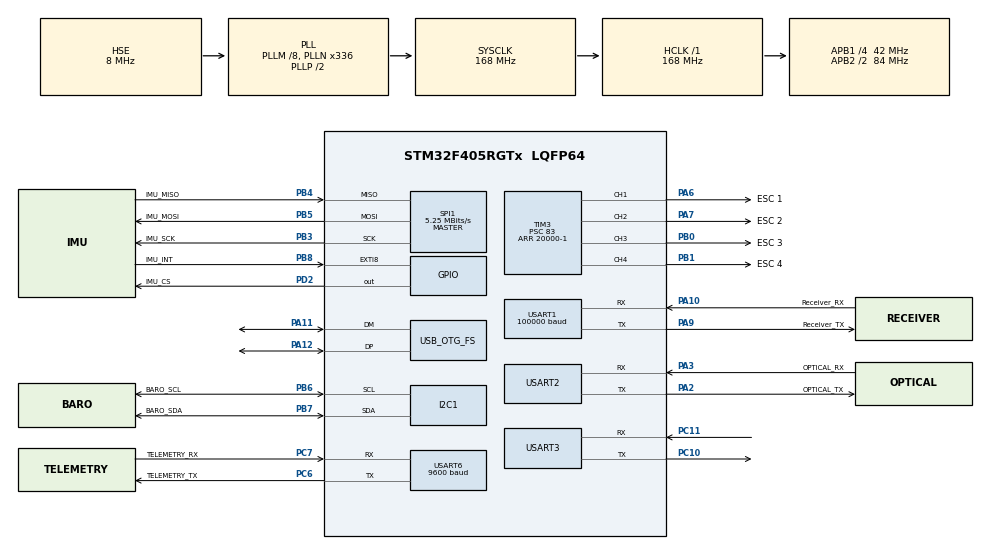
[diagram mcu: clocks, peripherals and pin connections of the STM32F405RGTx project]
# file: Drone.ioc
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Dma.Request0=USART2_RX
Dma.Request1=USART6_TX
Dma.Request2=USART2_TX
Dma.Request3=USART1_RX
Dma.Request4=SPI1_RX
Dma.Request5=SPI1_TX
Dma.SPI1_RX.4.Direction=DMA_PERIPH_TO_MEMORY
Dma.SPI1_RX.4.FIFOMode=DMA_FIFOMODE_DISABLE
Dma.SPI1_RX.4.Instance=DMA2_Stream0
Dma.SPI1_RX.4.MemDataAlignment=DMA_MDATAALIGN_BYTE
Dma.SPI1_RX.4.MemInc=DMA_MINC_ENABLE
Dma.SPI1_RX.4.Mode=DMA_NORMAL
Dma.SPI1_RX.4.PeriphDataAlignment=DMA_PDATAALIGN_BYTE
Dma.SPI1_RX.4.PeriphInc=DMA_PINC_DISABLE
Dma.SPI1_RX.4.Priority=DMA_PRIORITY_VERY_HIGH
Dma.SPI1_TX.5.Direction=DMA_MEMORY_TO_PERIPH
Dma.SPI1_TX.5.FIFOMode=DMA_FIFOMODE_DISABLE
Dma.SPI1_TX.5.Instance=DMA2_Stream3
Dma.SPI1_TX.5.MemDataAlignment=DMA_MDATAALIGN_BYTE
Dma.SPI1_TX.5.MemInc=DMA_MINC_ENABLE
Dma.SPI1_TX.5.Mode=DMA_NORMAL
Dma.SPI1_TX.5.PeriphDataAlignment=DMA_PDATAALIGN_BYTE
Dma.SPI1_TX.5.PeriphInc=DMA_PINC_DISABLE
Dma.SPI1_TX.5.Priority=DMA_PRIORITY_HIGH
Dma.USART1_RX.3.Direction=DMA_PERIPH_TO_MEMORY
Dma.USART1_RX.3.FIFOMode=DMA_FIFOMODE_DISABLE
Dma.USART1_RX.3.Instance=DMA2_Stream2
Dma.USART1_RX.3.MemDataAlignment=DMA_MDATAALIGN_BYTE
Dma.USART1_RX.3.MemInc=DMA_MINC_ENABLE
Dma.USART1_RX.3.Mode=DMA_CIRCULAR
Dma.USART1_RX.3.PeriphDataAlignment=DMA_PDATAALIGN_BYTE
Dma.USART1_RX.3.PeriphInc=DMA_PINC_DISABLE
Dma.USART1_RX.3.Priority=DMA_PRIORITY_HIGH
Dma.USART2_RX.0.Direction=DMA_PERIPH_TO_MEMORY
Dma.USART2_RX.0.FIFOMode=DMA_FIFOMODE_DISABLE
Dma.USART2_RX.0.Instance=DMA1_Stream5
Dma.USART2_RX.0.MemDataAlignment=DMA_MDATAALIGN_BYTE
Dma.USART2_RX.0.MemInc=DMA_MINC_ENABLE
Dma.USART2_RX.0.Mode=DMA_CIRCULAR
Dma.USART2_RX.0.PeriphDataAlignment=DMA_PDATAALIGN_BYTE
Dma.USART2_RX.0.PeriphInc=DMA_PINC_DISABLE
Dma.USART2_RX.0.Priority=DMA_PRIORITY_LOW
Dma.USART2_TX.2.Direction=DMA_MEMORY_TO_PERIPH
Dma.USART2_TX.2.FIFOMode=DMA_FIFOMODE_DISABLE
Dma.USART2_TX.2.Instance=DMA1_Stream6
Dma.USART2_TX.2.MemDataAlignment=DMA_MDATAALIGN_BYTE
Dma.USART2_TX.2.MemInc=DMA_MINC_ENABLE
Dma.USART2_TX.2.Mode=DMA_NORMAL
Dma.USART2_TX.2.PeriphDataAlignment=DMA_PDATAALIGN_BYTE
Dma.USART2_TX.2.PeriphInc=DMA_PINC_DISABLE
Dma.USART2_TX.2.Priority=DMA_PRIORITY_LOW
Dma.USART6_TX.1.Direction=DMA_MEMORY_TO_PERIPH
Dma.USART6_TX.1.FIFOMode=DMA_FIFOMODE_DISABLE
Dma.USART6_TX.1.Instance=DMA2_Stream6
Dma.USART6_TX.1.MemDataAlignment=DMA_MDATAALIGN_BYTE
Dma.USART6_TX.1.MemInc=DMA_MINC_ENABLE
Dma.USART6_TX.1.Mode=DMA_NORMAL
Dma.USART6_TX.1.PeriphDataAlignment=DMA_PDATAALIGN_BYTE
Dma.USART6_TX.1.PeriphInc=DMA_PINC_DISABLE
Dma.USART6_TX.1.Priority=DMA_PRIORITY_LOW
FREERTOS.INCLUDE_uxTaskGetStackHighWaterMark=1
FREERTOS.INCLUDE_vTaskDelayUntil=1
FREERTOS.Tasks01=telemTask,-1,1024,StartTelemTask,Default,NULL,Dynamic,NULL,NULL
FREERTOS.configCHECK_FOR_STACK_OVERFLOW=2
FREERTOS.configTOTAL_HEAP_SIZE=25000
FREERTOS.configUSE_MALLOC_FAILED_HOOK=1
FREERTOS.configUSE_NEWLIB_REENTRANT=1
I2C1.I2C_Mode=I2C_Fast
IWDG.Prescaler=IWDG_PRESCALER_32
IWDG.Reload=99
Mcu.Family=STM32F4
Mcu.Name=STM32F405RGTx
Mcu.Package=LQFP64
NVIC.DMA1_Stream5_IRQn=true\:6\:0\:true\:false\:true\:true\:false\:true\:true
NVIC.DMA1_Stream6_IRQn=true\:6\:0\:true\:false\:true\:true\:false\:true\:true
NVIC.DMA2_Stream0_IRQn=true\:5\:0\:false\:false\:true\:true\:false\:true\:true
NVIC.DMA2_Stream2_IRQn=true\:6\:0\:true\:false\:true\:true\:false\:true\:true
NVIC.DMA2_Stream3_IRQn=true\:5\:0\:false\:false\:true\:true\:false\:true\:true
NVIC.DMA2_Stream6_IRQn=true\:6\:0\:true\:false\:true\:true\:false\:true\:true
NVIC.EXTI9_5_IRQn=true\:5\:0\:false\:false\:true\:true\:true\:true\:true
NVIC.OTG_FS_IRQn=true\:6\:0\:true\:false\:true\:true\:false\:true\:true
NVIC.PriorityGroup=NVIC_PRIORITYGROUP_4
NVIC.TIM7_IRQn=true\:0\:0\:true\:false\:true\:false\:false\:true\:true
NVIC.TimeBase=TIM7_IRQn
NVIC.TimeBaseIP=TIM7
NVIC.USART1_IRQn=true\:7\:0\:true\:false\:true\:true\:true\:true\:true
NVIC.USART2_IRQn=true\:6\:0\:true\:false\:true\:true\:false\:true\:true
NVIC.USART6_IRQn=true\:6\:0\:true\:false\:true\:true\:false\:true\:true
PA10.GPIO_Label=Receiver_RX
PA10.Mode=Asynchronous
PA10.Signal=USART1_RX
PA11.Mode=Device_Only
PA11.Signal=USB_OTG_FS_DM
PA12.Mode=Device_Only
PA12.Signal=USB_OTG_FS_DP
PA13.Mode=Serial_Wire
PA13.Signal=SYS_JTMS-SWDIO
PA14.Mode=Serial_Wire
PA14.Signal=SYS_JTCK-SWCLK
PA2.GPIO_Label=OPTICAL_TX
PA2.Mode=Asynchronous
PA2.Signal=USART2_TX
PA3.GPIO_Label=OPTICAL_RX
PA3.Mode=Asynchronous
PA3.Signal=USART2_RX
PA6.GPIO_Label=ESC 1
PA6.Signal=S_TIM3_CH1
PA7.GPIO_Label=ESC 2
PA7.Signal=S_TIM3_CH2
PA9.GPIO_Label=Receiver_TX
PA9.Mode=Asynchronous
PA9.Signal=USART1_TX
PB0.GPIO_Label=ESC 3
PB0.Signal=S_TIM3_CH3
PB1.GPIO_Label=ESC 4
PB1.Signal=S_TIM3_CH4
PB3.GPIO_Label=IMU_SCK
PB3.Mode=Full_Duplex_Master
PB3.Signal=SPI1_SCK
PB4.GPIO_Label=IMU_MISO
PB4.Mode=Full_Duplex_Master
PB4.Signal=SPI1_MISO
PB5.GPIO_Label=IMU_MOSI
PB5.Mode=Full_Duplex_Master
PB5.Signal=SPI1_MOSI
PB6.GPIO_Label=BARO_SCL
PB6.Mode=I2C
PB6.Signal=I2C1_SCL
PB7.GPIO_Label=BARO_SDA
PB7.Mode=I2C
PB7.Signal=I2C1_SDA
PB8.GPIO_Label=IMU_INT
PB8.Signal=GPXTI8
PC10.GPIO_ModeDefaultPP=GPIO_MODE_AF_PP
PC10.GPIO_PuPd=GPIO_NOPULL
PC10.GPIO_Speed=GPIO_SPEED_FREQ_VERY_HIGH
PC10.Mode=Asynchronous
PC10.Signal=USART3_TX
PC11.GPIO_ModeDefaultPP=GPIO_MODE_AF_PP
PC11.GPIO_PuPd=GPIO_NOPULL
PC11.GPIO_Speed=GPIO_SPEED_FREQ_VERY_HIGH
PC11.Mode=Asynchronous
PC11.Signal=USART3_RX
PC6.GPIO_Label=TELEMETRY_TX
PC6.Mode=Asynchronous
PC6.Signal=USART6_TX
PC7.GPIO_Label=TELEMETRY_RX
PC7.Mode=Asynchronous
PC7.Signal=USART6_RX
PD2.GPIO_Label=IMU_CS
PD2.PinState=GPIO_PIN_SET
PD2.Signal=GPIO_Output
PH0-OSC_IN.Mode=HSE-External-Oscillator
PH0-OSC_IN.Signal=RCC_OSC_IN
PH1-OSC_OUT.Mode=HSE-External-Oscillator
PH1-OSC_OUT.Signal=RCC_OSC_OUT
ProjectManager.HeapSize=0x200
ProjectManager.StackSize=0x400
ProjectManager.TargetToolchain=STM32CubeIDE
RCC.48MHZClocksFreq_Value=48000000
RCC.AHBFreq_Value=168000000
RCC.APB1CLKDivider=RCC_HCLK_DIV4
RCC.APB1Freq_Value=42000000
RCC.APB1TimFreq_Value=84000000
RCC.APB2CLKDivider=RCC_HCLK_DIV2
RCC.APB2Freq_Value=84000000
RCC.APB2TimFreq_Value=168000000
RCC.CortexFreq_Value=168000000
RCC.HCLKFreq_Value=168000000
RCC.HSE_VALUE=8000000
RCC.HSI_VALUE=16000000
RCC.LSE_VALUE=32768
RCC.PLLM=8
RCC.PLLN=336
RCC.PLLQ=7
RCC.SYSCLKFreq_VALUE=168000000
RCC.SYSCLKSource=RCC_SYSCLKSOURCE_PLLCLK
RCC.VCOOutputFreq_Value=336000000
SH.S_TIM3_CH1.0=TIM3_CH1,PWM Generation1 CH1
SH.S_TIM3_CH2.0=TIM3_CH2,PWM Generation2 CH2
SH.S_TIM3_CH3.0=TIM3_CH3,PWM Generation3 CH3
SH.S_TIM3_CH4.0=TIM3_CH4,PWM Generation4 CH4
SPI1.BaudRatePrescaler=SPI_BAUDRATEPRESCALER_16
SPI1.CalculateBaudRate=5.25 MBits/s
SPI1.Direction=SPI_DIRECTION_2LINES
SPI1.Mode=SPI_MODE_MASTER
SPI1.VirtualType=VM_MASTER
TIM3.AutoReloadPreload=TIM_AUTORELOAD_PRELOAD_ENABLE
TIM3.Channel-PWM\ Generation1\ CH1=TIM_CHANNEL_1
TIM3.Channel-PWM\ Generation2\ CH2=TIM_CHANNEL_2
TIM3.Channel-PWM\ Generation3\ CH3=TIM_CHANNEL_3
TIM3.Channel-PWM\ Generation4\ CH4=TIM_CHANNEL_4
TIM3.Period=20000-1
TIM3.Prescaler=83
USART1.BaudRate=100000
USART1.Parity=PARITY_EVEN
USART1.StopBits=STOPBITS_2
USART1.VirtualMode=VM_ASYNC
USART1.WordLength=WORDLENGTH_9B
USART2.VirtualMode=VM_ASYNC
USART3.VirtualMode=VM_ASYNC
USART3.WordLength=WORDLENGTH_8B
USART6.BaudRate=9600
USART6.VirtualMode=VM_ASYNC
USART6.WordLength=WORDLENGTH_8B
USB_DEVICE.CLASS_NAME_FS=CDC
USB_DEVICE.VirtualMode-CDC_FS=Cdc
USB_DEVICE.VirtualModeFS=Cdc_FS
USB_OTG_FS.VirtualMode=Device_Only
VP_FREERTOS_VS_CMSIS_V1.Mode=CMSIS_V1
VP_IWDG_VS_IWDG.Mode=IWDG_Activate
VP_SYS_VS_tim7.Mode=TIM7
VP_TIM2_VS_ClockSourceINT.Mode=Internal
VP_TIM3_VS_ClockSourceINT.Mode=Internal
VP_USB_DEVICE_VS_USB_DEVICE_CDC_FS.Mode=CDC_FS
board=custom

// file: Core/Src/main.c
/* USER CODE BEGIN Header */
/**
  ******************************************************************************
  * @file           : main.c
  * @brief          : Main program body
  ******************************************************************************
  * @attention
  *
  * Copyright (c) 2026 STMicroelectronics.
  * All rights reserved.
  *
  * This software is licensed under terms that can be found in the LICENSE file
  * in the root directory of this software component.
  * If no LICENSE file comes with this software, it is provided AS-IS.
  *
  ******************************************************************************
  */
/* USER CODE END Header */
#include "main.h"
#include "cmsis_os.h"
#include "dma.h"
#include "i2c.h"
#include "spi.h"
#include "tim.h"
#include "usart.h"
#include "usb_device.h"
#include "gpio.h"

/* USER CODE BEGIN Includes */
#include "app_main.h"
#include "board_hardware_layer/pwm_esc.h"
/* USER CODE END Includes */

void SystemClock_Config(void);
void MX_FREERTOS_Init(void);

int main(void)
{

  /* MCU Configuration--------------------------------------------------------*/

  /* Reset of all peripherals, Initializes the Flash interface and the Systick. */
  HAL_Init();

  /* Configure the system clock */
  SystemClock_Config();

  /* Initialize all configured peripherals */
  MX_GPIO_Init();
  MX_DMA_Init();
  MX_SPI1_Init();
  MX_USART1_UART_Init();
  MX_USART2_UART_Init();
  MX_USART3_UART_Init();
  MX_USART6_UART_Init();
  MX_I2C1_Init();
  MX_TIM2_Init();
  MX_TIM3_Init();
  /* USER CODE BEGIN 2 */
  app_init();
  /* USER CODE END 2 */

  /* Call init function for freertos objects (in cmsis_os2.c) */
  MX_FREERTOS_Init();

  /* Start scheduler */
  osKernelStart();

  /* We should never get here as control is now taken by the scheduler */

  /* Infinite loop */
  while (1)
  {

  }
}

void SystemClock_Config(void)
{
  RCC_OscInitTypeDef RCC_OscInitStruct = {0};
  RCC_ClkInitTypeDef RCC_ClkInitStruct = {0};

  /** Configure the main internal regulator output voltage
  */
  __HAL_RCC_PWR_CLK_ENABLE();
  __HAL_PWR_VOLTAGESCALING_CONFIG(PWR_REGULATOR_VOLTAGE_SCALE1);

  /** Initializes the RCC Oscillators according to the specified parameters
  * in the RCC_OscInitTypeDef structure.
  */
  RCC_OscInitStruct.OscillatorType = RCC_OSCILLATORTYPE_LSI|RCC_OSCILLATORTYPE_HSE;
  RCC_OscInitStruct.HSEState = RCC_HSE_ON;
  RCC_OscInitStruct.LSIState = RCC_LSI_ON;
  RCC_OscInitStruct.PLL.PLLState = RCC_PLL_ON;
  RCC_OscInitStruct.PLL.PLLSource = RCC_PLLSOURCE_HSE;
  RCC_OscInitStruct.PLL.PLLM = 8;
  RCC_OscInitStruct.PLL.PLLN = 336;
  RCC_OscInitStruct.PLL.PLLP = RCC_PLLP_DIV2;
  RCC_OscInitStruct.PLL.PLLQ = 7;
  if (HAL_RCC_OscConfig(&RCC_OscInitStruct) != HAL_OK)
  {
    Error_Handler();
  }

  /** Initializes the CPU, AHB and APB buses clocks
  */
  RCC_ClkInitStruct.ClockType = RCC_CLOCKTYPE_HCLK|RCC_CLOCKTYPE_SYSCLK
                              |RCC_CLOCKTYPE_PCLK1|RCC_CLOCKTYPE_PCLK2;
  RCC_ClkInitStruct.SYSCLKSource = RCC_SYSCLKSOURCE_PLLCLK;
  RCC_ClkInitStruct.AHBCLKDivider = RCC_SYSCLK_DIV1;
  RCC_ClkInitStruct.APB1CLKDivider = RCC_HCLK_DIV4;
  RCC_ClkInitStruct.APB2CLKDivider = RCC_HCLK_DIV2;

  if (HAL_RCC_ClockConfig(&RCC_ClkInitStruct, FLASH_LATENCY_5) != HAL_OK)
  {
    Error_Handler();
  }
}

void HAL_TIM_PeriodElapsedCallback(TIM_HandleTypeDef *htim)
{
  if (htim->Instance == TIM7)
  {
    HAL_IncTick();
  }
  /* USER CODE BEGIN Callback 1 */
  if (htim->Instance == TIM7)
  {
    pwm_esc_watchdog_1ms();  /* NVIC 0: still runs if task_ctrl stalls or BASEPRI is raised */
  }
  /* USER CODE END Callback 1 */
}

void Error_Handler(void)
{
  /* USER CODE BEGIN Error_Handler_Debug */
  /* User can add his own implementation to report the HAL error return state */
  esc_emergency_stop();  /* no MCU watchdog: stop the motors before halting */
  __disable_irq();
  while (1)
  {
  }
  /* USER CODE END Error_Handler_Debug */
}

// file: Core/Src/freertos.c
/* USER CODE BEGIN Header */
/**
  ******************************************************************************
  * File Name          : freertos.c
  * Description        : Code for freertos applications
  ******************************************************************************
  * @attention
  *
  * Copyright (c) 2026 STMicroelectronics.
  * All rights reserved.
  *
  * This software is licensed under terms that can be found in the LICENSE file
  * in the root directory of this software component.
  * If no LICENSE file comes with this software, it is provided AS-IS.
  *
  ******************************************************************************
  */
/* USER CODE END Header */

#include "FreeRTOS.h"
#include "task.h"
#include "main.h"
#include "cmsis_os.h"

/* USER CODE BEGIN Includes */
#include "app_main.h"
/* USER CODE END Includes */

osThreadId telemTaskHandle;

void StartTelemTask(void const * argument);

extern void MX_USB_DEVICE_Init(void);
void MX_FREERTOS_Init(void); /* (MISRA C 2004 rule 8.1) */

/* GetIdleTaskMemory prototype (linked to static allocation support) */
void vApplicationGetIdleTaskMemory( StaticTask_t **ppxIdleTaskTCBBuffer, StackType_t **ppxIdleTaskStackBuffer, uint32_t *pulIdleTaskStackSize );

/* Hook prototypes */
void vApplicationStackOverflowHook(xTaskHandle xTask, signed char *pcTaskName);
void vApplicationMallocFailedHook(void);

/* USER CODE BEGIN 4 */
__weak void vApplicationStackOverflowHook(xTaskHandle xTask, signed char *pcTaskName)
{
   /* Run time stack overflow checking is performed if
   configCHECK_FOR_STACK_OVERFLOW is defined to 1 or 2. This hook function is
   called if a stack overflow is detected. */
}
/* USER CODE END 4 */

/* USER CODE BEGIN 5 */
__weak void vApplicationMallocFailedHook(void)
{
   /* vApplicationMallocFailedHook() will only be called if
   configUSE_MALLOC_FAILED_HOOK is set to 1 in FreeRTOSConfig.h. It is a hook
   function that will get called if a call to pvPortMalloc() fails.
   pvPortMalloc() is called internally by the kernel whenever a task, queue,
   timer or semaphore is created. It is also called by various parts of the
   demo application. If heap_1.c or heap_2.c are used, then the size of the
   heap available to pvPortMalloc() is defined by configTOTAL_HEAP_SIZE in
   FreeRTOSConfig.h, and the xPortGetFreeHeapSize() API function can be used
   to query the size of free heap space that remains (although it does not
   provide information on how the remaining heap might be fragmented). */
}
/* USER CODE END 5 */

/* USER CODE BEGIN GET_IDLE_TASK_MEMORY */
static StaticTask_t xIdleTaskTCBBuffer;
static StackType_t xIdleStack[configMINIMAL_STACK_SIZE];

void vApplicationGetIdleTaskMemory( StaticTask_t **ppxIdleTaskTCBBuffer, StackType_t **ppxIdleTaskStackBuffer, uint32_t *pulIdleTaskStackSize )
{
  *ppxIdleTaskTCBBuffer = &xIdleTaskTCBBuffer;
  *ppxIdleTaskStackBuffer = &xIdleStack[0];
  *pulIdleTaskStackSize = configMINIMAL_STACK_SIZE;
  /* place for user code */
}
/* USER CODE END GET_IDLE_TASK_MEMORY */

void MX_FREERTOS_Init(void) {

  /* Create the thread(s) */
  /* definition and creation of telemTask */
  osThreadDef(telemTask, StartTelemTask, osPriorityBelowNormal, 0, 1024);
  telemTaskHandle = osThreadCreate(osThread(telemTask), NULL);

}

void StartTelemTask(void const * argument)
{
  /* init code for USB_DEVICE */
  MX_USB_DEVICE_Init();
  /* USER CODE BEGIN StartTelemTask */
  app_telem_task(argument);
  /* USER CODE END StartTelemTask */
}
